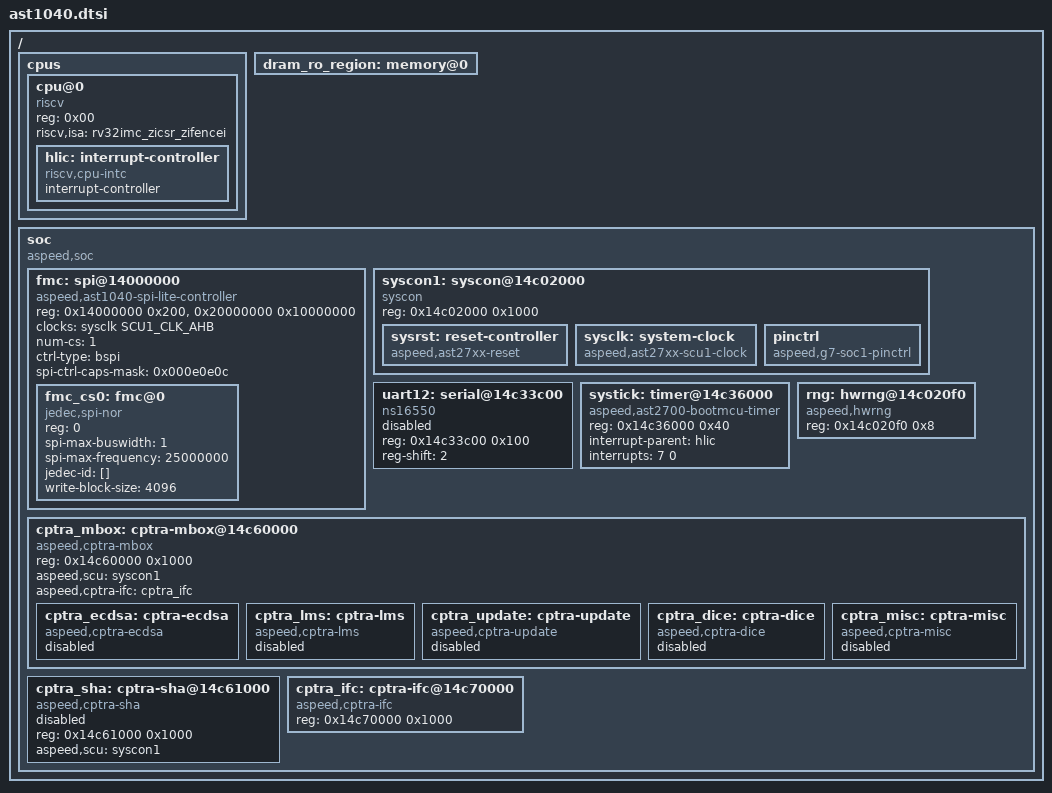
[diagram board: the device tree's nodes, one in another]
/*
 * SPDX-License-Identifier: Apache-2.0
 *
 * Copyright (c) 2023 ASPEED Technology Inc.
 */

#include <mem.h>
#include <aspeed/ast1040-irq.h>
#include <zephyr/dt-bindings/clock/ast27xx_clock.h>
#include <zephyr/dt-bindings/reset/ast27xx_reset.h>

/ {
	cpus {
		#address-cells = <1>;
		#size-cells = <0>;

		cpu@0 {
			device_type = "cpu";
			reg = <0x00>;
			status = "okay";
			compatible = "riscv";
			riscv,isa = "rv32imc_zicsr_zifencei";

			hlic: interrupt-controller {
				compatible = "riscv,cpu-intc";
				#address-cells = <0>;
				#interrupt-cells = <1>;
				interrupt-controller;
			};
		};
	};

	dram_ro_region: memory@0 {
		device_type = "memory";
	};

	soc {
		compatible = "aspeed,soc", "simple-bus";
		#address-cells = <0x01>;
		#size-cells = <0x01>;
		ranges;

		fmc: spi@14000000 {
			compatible = "aspeed,ast1040-spi-lite-controller";
			reg = <0x14000000 0x200>, <0x20000000 0x10000000>;
			reg-names = "ctrl_reg", "spi_mmap";
			clocks = <&sysclk SCU1_CLK_AHB>;
			num-cs = <1>;
			ctrl-type = "bspi";
			#address-cells = <1>;
			#size-cells = <0>;
			spi-ctrl-caps-mask = <0x000e0e0c>;

			fmc_cs0: fmc@0 {
				compatible = "jedec,spi-nor";
				reg = <0>;
				spi-max-buswidth = <1>;
				spi-max-frequency = <25000000>;
				jedec-id = [];
				write-block-size = <4096>;
			};
		};

		syscon1: syscon@14c02000 {
			compatible = "syscon";
			reg = <0x14c02000 0x1000>;

			sysrst: reset-controller {
				compatible = "aspeed,ast27xx-reset";
				#reset-cells = <1>;
			};

			sysclk: system-clock {
				compatible = "aspeed,ast27xx-scu1-clock";
				#clock-cells = <1>;
			};

			pinctrl: pinctrl {
				compatible = "aspeed,g7-soc1-pinctrl";
			};
		};

		uart12: serial@14c33c00 {
			compatible = "ns16550";
			reg = <0x14c33c00 0x100>;
			status = "disabled";
			reg-shift = <2>;
		};

		systick: timer@14c36000 {
			compatible = "aspeed,ast2700-bootmcu-timer";
			reg = <0x14c36000 0x40>;
			interrupt-parent = <&hlic>;
			interrupts = <7 0>;
		};

		rng: hwrng@14c020f0 {
			compatible = "aspeed,hwrng";
			reg = <0x14c020f0 0x8>;
		};

		cptra_mbox: cptra-mbox@14c60000 {
			compatible = "aspeed,cptra-mbox";
			reg = <0x14c60000 0x1000>;
			aspeed,scu = <&syscon1>;
			aspeed,cptra-ifc = <&cptra_ifc>;

			cptra_ecdsa: cptra-ecdsa {
				compatible = "aspeed,cptra-ecdsa";
				status = "disabled";
			};

			cptra_lms: cptra-lms {
				compatible = "aspeed,cptra-lms";
				status = "disabled";
			};

			cptra_update: cptra-update {
				compatible = "aspeed,cptra-update";
				status = "disabled";
			};

			cptra_dice: cptra-dice {
				compatible = "aspeed,cptra-dice";
				status = "disabled";
			};

			cptra_misc: cptra-misc {
				compatible = "aspeed,cptra-misc";
				status = "disabled";
			};
		};

		cptra_sha: cptra-sha@14c61000 {
			compatible = "aspeed,cptra-sha";
			reg = <0x14c61000 0x1000>;
			aspeed,scu = <&syscon1>;
			status = "disabled";
		};

		cptra_ifc: cptra-ifc@14c70000 {
			compatible = "aspeed,cptra-ifc";
			reg = <0x14c70000 0x1000>;
		};

	};
};
